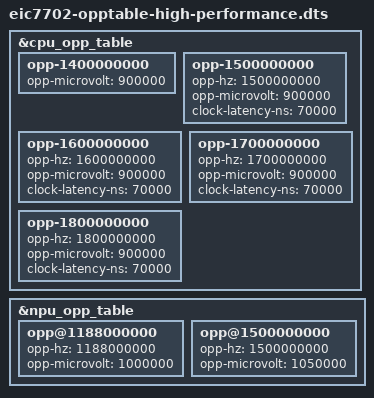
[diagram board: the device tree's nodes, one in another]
/* SPDX-License-Identifier: GPL-2.0 */
/*
 * Copyright 2026, Beijing ESWIN Computing Technology Co., Ltd.. All rights reserved.
 *
 */

/dts-v1/;
/plugin/;

/ {
	fragment@0 {
		target =  <&cpu_opp_table>;
		__overlay__ {
			opp-1400000000 {
				opp-microvolt = <900000>;
			};
			opp-1500000000 {
				opp-hz = /bits/ 64 <1500000000>;
				opp-microvolt = <900000>;
				clock-latency-ns = <70000>;
			};
			opp-1600000000 {
				opp-hz = /bits/ 64 <1600000000>;
				opp-microvolt = <900000>;
				clock-latency-ns = <70000>;
			};
			opp-1700000000 {
				opp-hz = /bits/ 64 <1700000000>;
				opp-microvolt = <900000>;
				clock-latency-ns = <70000>;
			};
			opp-1800000000 {
				opp-hz = /bits/ 64 <1800000000>;
				opp-microvolt = <900000>;
				clock-latency-ns = <70000>;
			};
		};
	};

	fragment@1 {
		target =  <&npu_opp_table>;
		__overlay__ {
			opp@1188000000 {
				opp-hz = /bits/ 64 <1188000000>;
				opp-microvolt = <1000000>;
			};
			opp@1500000000 {
				opp-hz = /bits/ 64 <1500000000>;
				opp-microvolt = <1050000>;
			};
		};
	};
};
